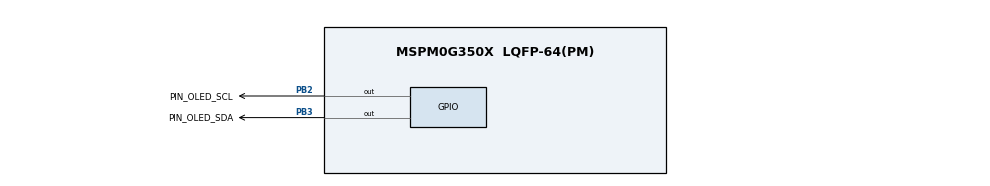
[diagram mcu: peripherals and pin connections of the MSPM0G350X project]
/**
 * @cliArgs --device "MSPM0G350X" --part "Default" --package "LQFP-64(PM)" --product "mspm0_sdk@2.05.01.00"
 * @versions {"tool":"1.24.0+4110"}
 */

/**
 * Import the modules used in this configuration.
 */
const GPIO   = scripting.addModule("/ti/driverlib/GPIO", {}, false);
const GPIO1  = GPIO.addInstance();
const SYSCTL = scripting.addModule("/ti/driverlib/SYSCTL");

/**
 * Write custom configuration values to the imported modules.
 */
const divider7       = system.clockTree["PLL_PDIV"];
divider7.divideValue = 2;

const divider9       = system.clockTree["UDIV"];
divider9.divideValue = 2;

const multiplier2         = system.clockTree["PLL_QDIV"];
multiplier2.multiplyValue = 5;

const mux8       = system.clockTree["HSCLKMUX"];
mux8.inputSelect = "HSCLKMUX_SYSPLL2X";

GPIO1.$name                         = "GPIO_OLED";
GPIO1.associatedPins.create(2);
GPIO1.associatedPins[0].$name       = "PIN_OLED_SCL";
GPIO1.associatedPins[0].pin.$assign = "PB2";
GPIO1.associatedPins[1].$name       = "PIN_OLED_SDA";
GPIO1.associatedPins[1].pin.$assign = "PB3";

const Board = scripting.addModule("/ti/driverlib/Board", {}, false);

SYSCTL.forceDefaultClkConfig = true;
SYSCTL.clockTreeEn           = true;
scripting.suppress("For best practices when the CPUCLK is running at 32MHz and above, clear the flash status bit using DL_FlashCTL_executeClearStatus\\(\\) before executing any flash operation\\. Otherwise there may be false positives\\.", SYSCTL);

/**
 * Pinmux solution for unlocked pins/peripherals. This ensures that minor changes to the automatic solver in a future
 * version of the tool will not impact the pinmux you originally saw.  These lines can be completely deleted in order to
 * re-solve from scratch.
 */
Board.peripheral.$suggestSolution          = "DEBUGSS";
Board.peripheral.swclkPin.$suggestSolution = "PA20";
Board.peripheral.swdioPin.$suggestSolution = "PA19";
